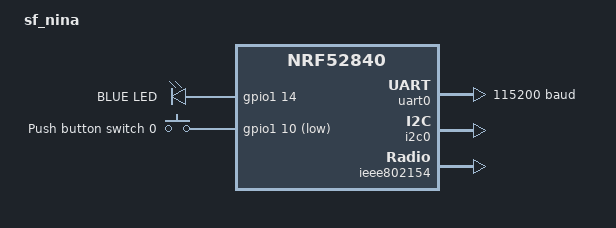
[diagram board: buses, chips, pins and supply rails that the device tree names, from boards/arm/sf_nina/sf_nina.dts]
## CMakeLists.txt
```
# SPDX-License-Identifier: Apache-2.0

cmake_minimum_required(VERSION 3.20.0)

find_package(Zephyr REQUIRED HINTS $ENV{ZEPHYR_BASE})
project(hello_world)

#target_sources(app PRIVATE src/main.c)

FILE(GLOB app_sources src/*.c)
# NORDIC SDK APP START
target_sources(app PRIVATE ${app_sources})
# NORDIC SDK APP END
```

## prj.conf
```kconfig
# nothing here

CONFIG_GPIO=y
CONFIG_I2C=y
CONFIG_CBPRINTF_FP_SUPPORT=y
```

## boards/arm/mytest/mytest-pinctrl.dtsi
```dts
&pinctrl {
	uart0_default: uart0_default {
		group1 {
			psels = <NRF_PSEL(UART_TX, 0, 6)>;				
		};
		group2 {
			psels = <NRF_PSEL(UART_RX, 0, 8)>;				
			bias-pull-up;
		};
	};

	uart0_sleep: uart0_sleep {
		group1 {
			psels = <NRF_PSEL(UART_TX, 0, 6)>,
				<NRF_PSEL(UART_RX, 0, 8)>;				
			low-power-enable;
		};
	};
};
```

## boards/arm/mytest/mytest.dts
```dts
// Copyright (c) 2023 Nordic Semiconductor ASA
// SPDX-License-Identifier: Apache-2.0

/dts-v1/;
#include <nordic/nrf52840_qiaa.dtsi>
#include "mytest-pinctrl.dtsi"

/ {
	model = "mytest";
	compatible = "mytest";

	chosen {
		zephyr,sram = &sram0;
		zephyr,flash = &flash0;
		zephyr,code-partition = &slot0_partition;
		zephyr,console = &uart0;
		zephyr,shell-uart = &uart0;
		zephyr,uart-mcumgr = &uart0;
		zephyr,bt-mon-uart = &uart0;
		zephyr,bt-c2h-uart = &uart0;
	};

	leds {
		compatible = "gpio-leds";
		led0: led_0 {
			gpios = <&gpio0 13 GPIO_ACTIVE_LOW>;
			label = "Green LED 0";
		};
	};
};

&uart0 {
	compatible = "nordic,nrf-uarte";
	status = "okay";
	current-speed = <115200>;
	pinctrl-0 = <&uart0_default>;
	pinctrl-1 = <&uart0_sleep>;
	pinctrl-names = "default", "sleep";
};


&flash0 {
	partitions {
		compatible = "fixed-partitions";
		#address-cells = <1>;
		#size-cells = <1>;

		boot_partition: partition@0 {
			label = "mcuboot";
			reg = <0x0 0xc000>;
		};
		slot0_partition: partition@c000 {
			label = "image-0";
			reg = <0xc000 0x72000>;
		};
		slot1_partition: partition@7e000 {
			label = "image-1";
			reg = <0x7e000 0x72000>;
		};
		scratch_partition: partition@f0000 {
			label = "image-scratch";
			reg = <0xf0000 0xa000>;
		};
		storage_partition: partition@fa000 {
			label = "storage";
			reg = <0xfa000 0x6000>;
		};
	};
};
```

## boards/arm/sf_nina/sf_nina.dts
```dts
// Copyright (c) 2023 Nordic Semiconductor ASA
// SPDX-License-Identifier: Apache-2.0

/dts-v1/;
#include <nordic/nrf52840_qiaa.dtsi>
#include "sf_nina-pinctrl.dtsi"

/ {
	model = "sf_nina";
	compatible = "sf,sf-nina";

	chosen {
		zephyr,sram = &sram0;
		zephyr,flash = &flash0;
		zephyr,code-partition = &slot0_partition;
		zephyr,console = &uart0;
		zephyr,shell-uart = &uart0;
		zephyr,uart-mcumgr = &uart0;
		zephyr,bt-mon-uart = &uart0;
		zephyr,bt-c2h-uart = &uart0;
		zephyr,ieee802154 = &ieee802154;
	};

	leds {
		compatible = "gpio-leds";
		ledblue: led_0 {
			gpios = <&gpio1 14 0>;
			label = "BLUE LED";
		};
	};

	buttons {
		compatible = "gpio-keys";
		button0: button_0 {
			gpios = <&gpio1 10 (GPIO_PULL_UP | GPIO_ACTIVE_LOW)>;
			label = "Push button switch 0";
		};
	};

	aliases {
		ledblue = &ledblue;	
		button0 = &button0;	
	};
};

&gpiote {
	status = "okay";
};

&gpio0 {
	status = "okay";
};

&gpio1 {
	status = "okay";
};

&uart0 {
	compatible = "nordic,nrf-uarte";
	status = "okay";
	current-speed = <115200>;
	pinctrl-0 = <&uart0_default>;
	pinctrl-1 = <&uart0_sleep>;
	pinctrl-names = "default", "sleep";
};

&i2c0 {
	compatible = "nordic,nrf-twi";
	status = "okay";
	pinctrl-0 = <&i2c0_default>;
	pinctrl-1 = <&i2c0_sleep>;
	pinctrl-names = "default", "sleep";
};


&flash0 {
	partitions {
		compatible = "fixed-partitions";
		#address-cells = <1>;
		#size-cells = <1>;

		boot_partition: partition@0 {
			label = "mcuboot";
			reg = <0x0 0xc000>;
		};
		slot0_partition: partition@c000 {
			label = "image-0";
			reg = <0xc000 0x72000>;
		};
		slot1_partition: partition@7e000 {
			label = "image-1";
			reg = <0x7e000 0x72000>;
		};
		scratch_partition: partition@f0000 {
			label = "image-scratch";
			reg = <0xf0000 0xa000>;
		};
		storage_partition: partition@fa000 {
			label = "storage";
			reg = <0xfa000 0x6000>;
		};
	};
};

&ieee802154 {
	status = "okay";
};
```

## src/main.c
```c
/*
 * Copyright (c) 2012-2014 Wind River Systems, Inc.
 *
 * SPDX-License-Identifier: Apache-2.0
 */

#include <zephyr/kernel.h>

#include "pin_manager.h"
#include "ism330.h"

#define SLEEP_MS 200


// Define the callback function
void button_pressed(const struct device *dev, struct gpio_callback *cb, uint32_t pins)
{
	LEDBLUE_Toggle();
}

// Define a variable of type static struct gpio_callback
static struct gpio_callback button_cb_data;

void main(void)
{
	uint8_t val;

	printk("Hello World from my new board! %s\n", CONFIG_BOARD);

	PIN_MANAGER_Initialize();
	ISM_Initialize();


	// Initialize the gpio_callback variable  
	gpio_init_callback(&button_cb_data, button_pressed, BIT(button.pin)); 	
	
	// Add the callback function by calling gpio_add_callback()
 	gpio_add_callback(button.port, &button_cb_data);

	LEDBLUE_SetHigh();
	k_msleep(SLEEP_MS);	
	LEDBLUE_SetLow();


/*
	//Test ledblue
	while(1) {
		LEDBLUE_SetHigh();
		k_msleep(SLEEP_MS);	
		LEDBLUE_SetLow();
		k_msleep(SLEEP_MS);	

	}
*/

/*
	//Test button as dig. input
	while(1) {
		val = gpio_pin_get_dt(&button);
		if (val) {
			LEDBLUE_SetHigh();
		} else {
			LEDBLUE_SetLow();
		}
		k_msleep(SLEEP_MS);

		printRawAccel();
	}
*/

	//Tetst button as interrupt
	while (1) {
		printRawAccel();
		k_msleep(SLEEP_MS);
	}

}
```

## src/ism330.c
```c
#include "ism330.h"
#include <stdlib.h>
//#include "math.h"

int16_t data_raw_acceleration[3];
int16_t data_raw_angular_rate[3];
//static int16_t data_raw_temperature;
float acceleration_mg[3];
float angular_rate_mdps[3];
//static float temperature_degC;
uint8_t whoamI, rst;
//static uint8_t tx_buffer[1000];

gyro_angle ISM_gyro_angle;
accel ISM_accel;

stmdev_ctx_t dev_ctx;

int32_t platform_write(void *handle, uint8_t reg, const uint8_t *bufp,
                              uint16_t len)
{
#if defined(NUCLEO_F411RE)
  HAL_I2C_Mem_Write(handle, ISM330DHCX_I2C_ADD_H, reg,
                    I2C_MEMADD_SIZE_8BIT, (uint8_t*) bufp, len, 1000);
#elif defined(STEVAL_MKI109V3)
  HAL_GPIO_WritePin(CS_up_GPIO_Port, CS_up_Pin, GPIO_PIN_RESET);
  HAL_SPI_Transmit(handle, &reg, 1, 1000);
  HAL_SPI_Transmit(handle, (uint8_t*) bufp, len, 1000);
  HAL_GPIO_WritePin(CS_up_GPIO_Port, CS_up_Pin, GPIO_PIN_SET);
#elif defined(SPC584B_DIS)
  i2c_lld_write(handle,  ISM330DHCX_I2C_ADD_H & 0xFE, reg,
               (uint8_t*) bufp, len);
#endif

	uint8_t buffer[16];
	uint8_t i,aux;
	int32_t ret; 

	buffer[0] = reg;

	aux = 1;
	for (i = 0; i < len; i++) {
		buffer[aux] = bufp[i];
		aux++;
	}
	//SPI_transaction(buffer, aux);

	ret = i2c_write_dt(&dev_i2c, buffer, aux);

	return 0;
}

/*
 * @brief  Read generic device register (platform dependent)
 *
 * @param  handle    customizable argument. In this examples is used in
 *                   order to select the correct sensor bus handler.
 * @param  reg       register to read
 * @param  bufp      pointer to buffer that store the data read
 * @param  len       number of consecutive register to read
 *
 */
int32_t platform_read(void *handle, uint8_t reg, uint8_t *bufp,
                             uint16_t len)
{
#if defined(NUCLEO_F411RE)
  HAL_I2C_Mem_Read(handle, ISM330DHCX_I2C_ADD_H, reg,
                   I2C_MEMADD_SIZE_8BIT, bufp, len, 1000);
#elif defined(STEVAL_MKI109V3)
  reg |= 0x80;
  HAL_GPIO_WritePin(CS_up_GPIO_Port, CS_up_Pin, GPIO_PIN_RESET);
  HAL_SPI_Transmit(handle, &reg, 1, 1000);
  HAL_SPI_Receive(handle, bufp, len, 1000);
  HAL_GPIO_WritePin(CS_up_GPIO_Port, CS_up_Pin, GPIO_PIN_SET);
#elif defined(SPC584B_DIS)
  i2c_lld_read(handle, ISM330DHCX_I2C_ADD_H & 0xFE, reg, bufp, len);
#endif

	uint8_t buffer[16];
	uint8_t i,aux;
	uint32_t ret;

	//uint8_t reading[1]= {0};
    uint8_t sensor_regs[1];
	
	sensor_regs[0] = reg;
	ret = i2c_write_read_dt(&dev_i2c,&sensor_regs[0],1,bufp,len);

	return 0;
}

int ISM_Initialize(void)
{
 	
	//printk("I2C Accel Tests\n");

	if (!device_is_ready(dev_i2c.bus)) {
		printk("I2C bus %s is not ready!\n\r",dev_i2c.bus->name);		
    return 0;
	}


	  /* Initialize mems driver interface */
	dev_ctx.write_reg = platform_write;
	dev_ctx.read_reg = platform_read;

	k_msleep(SLEEP_MS);

	/* Check device ID */
	ism330dhcx_device_id_get(&dev_ctx, &whoamI);
	printk("ISM whoiam %x\n", whoamI);

  /* Restore default configuration */
  ism330dhcx_reset_set(&dev_ctx, PROPERTY_ENABLE);
  do {
    ism330dhcx_reset_get(&dev_ctx, &rst);
    printk("ISM resetting dev %x\n", rst);
  } while (rst);

  /* Start device configuration. */
  ism330dhcx_device_conf_set(&dev_ctx, PROPERTY_ENABLE);
  
  /* Enable Block Data Update */
  ism330dhcx_block_data_update_set(&dev_ctx, PROPERTY_ENABLE);

  /* Set Output Data Rate */
  ism330dhcx_xl_data_rate_set(&dev_ctx, ISM330DHCX_XL_ODR_104Hz);
  ism330dhcx_gy_data_rate_set(&dev_ctx, ISM330DHCX_GY_ODR_104Hz);

  /* Set full scale */
  ism330dhcx_xl_full_scale_set(&dev_ctx, ISM330DHCX_2g);
  ism330dhcx_gy_full_scale_set(&dev_ctx, ISM330DHCX_2000dps);

  /* Configure filtering chain(No aux interface)
  *
  * Accelerometer - LPF1 + LPF2 path
  */
  ism330dhcx_xl_hp_path_on_out_set(&dev_ctx, ISM330DHCX_LP_ODR_DIV_100);
  ism330dhcx_xl_filter_lp2_set(&dev_ctx, PROPERTY_ENABLE);

  //ism330dhcx_g
  ism330dhcx_gy_lp1_bandwidth_set(&dev_ctx, ISM330DHCX_MEDIUM);
  ism330dhcx_gy_filter_lp1_set(&dev_ctx, PROPERTY_ENABLE);

  ISM_gyro_angle.p = 0;
  ISM_gyro_angle.r = 0;
  ISM_gyro_angle.y = 0;

  ISM_accel.last_accel_y = 0;
  ISM_accel.diff_accel_y = 0;

  ISM_accel.mov_av_buf[0] = 0;
  ISM_accel.mov_av_buf[1] = 0;
  ISM_accel.mov_av_buf[2] = 0;
  ISM_accel.mov_av_buf[3] = 0;

}

void printRawAccel(void)
{
  uint8_t reg;

	ism330dhcx_xl_flag_data_ready_get(&dev_ctx, &reg);

	if (reg) {
    // Read acceleration field data
	  memset(data_raw_acceleration, 0x00, 3 * sizeof(int16_t));
	  ism330dhcx_acceleration_raw_get(&dev_ctx, data_raw_acceleration);
	  acceleration_mg[0] = ism330dhcx_from_fs2g_to_mg(data_raw_acceleration[0]);
	  acceleration_mg[1] = ism330dhcx_from_fs2g_to_mg(data_raw_acceleration[1]);
	  acceleration_mg[2] = ism330dhcx_from_fs2g_to_mg(data_raw_acceleration[2]);
	  //sprintf((char *)tx_buffer,"Acceleration [mg]:%4.2f\t%4.2f\t%4.2f\r\n", acceleration_mg[0], acceleration_mg[1], acceleration_mg[2]);
	  printf("Accel [mg]:%4.2f\t%4.2f\t%4.2f\r\n", acceleration_mg[0], acceleration_mg[1], acceleration_mg[2]);
	  //printf("Accel z [mg]:%4.2f\n", (acceleration_mg[2]+119));
  }

}

void printRawAng(void)
{
  uint8_t reg;

  ism330dhcx_gy_flag_data_ready_get(&dev_ctx, &reg);

	if (reg) {
    // Read angular rate field data
		memset(data_raw_angular_rate, 0x00, 3 * sizeof(int16_t));
		ism330dhcx_angular_rate_raw_get(&dev_ctx, data_raw_angular_rate);
		angular_rate_mdps[0] = ism330dhcx_from_fs2000dps_to_mdps(data_raw_angular_rate[0]);
		angular_rate_mdps[1] = ism330dhcx_from_fs2000dps_to_mdps(data_raw_angular_rate[1]);
		angular_rate_mdps[2] = ism330dhcx_from_fs2000dps_to_mdps(data_raw_angular_rate[2]);
		//printf("Angrate [mdps]:%4.2f\t%4.2f\t%4.2f\r\n", angular_rate_mdps[0], angular_rate_mdps[1], angular_rate_mdps[2]);
    //printf("Angrate [mdps]:%6.0f\t%6.0f\t%6.0f\r\n", angular_rate_mdps[0], angular_rate_mdps[1], angular_rate_mdps[2]);
    printf("Angrate [dps]:%3.1f\t%3.1f\t%3.1f\r\n", angular_rate_mdps[0]/1000, angular_rate_mdps[1]/1000, angular_rate_mdps[2]/1000);
  }

}

float_t gyro_fs2000dps_to_dps(int16_t lsb)
{
  //return ((float_t)lsb * 70.0f);
  return ((float_t)lsb * 0.07f);
}

int getRawAngDeg(void)
{
uint8_t reg;
int16_t p,r,y;

  ism330dhcx_gy_flag_data_ready_get(&dev_ctx, &reg);

	if (reg) {
    
		memset(data_raw_angular_rate, 0x00, 3 * sizeof(int16_t));
		ism330dhcx_angular_rate_raw_get(&dev_ctx, data_raw_angular_rate);
		angular_rate_mdps[0] = gyro_fs2000dps_to_dps(data_raw_angular_rate[0]);
		angular_rate_mdps[1] = gyro_fs2000dps_to_dps(data_raw_angular_rate[1]);
		angular_rate_mdps[2] = gyro_fs2000dps_to_dps(data_raw_angular_rate[2]);
		
    
//    printf("Angrate [dps]:%3.1f\t%3.1f\t%3.1f\r\n", angular_rate_mdps[0], angular_rate_mdps[1], angular_rate_mdps[2]);
    
    ISM_gyro_angle.r = angular_rate_mdps[0]; //Y movement mouse
    ISM_gyro_angle.p = angular_rate_mdps[1]; // to scroll wheel
    ISM_gyro_angle.y = angular_rate_mdps[2]; //X movement mouse

    if (abs(ISM_gyro_angle.r) || abs(ISM_gyro_angle.p) || abs(ISM_gyro_angle.y)) {
      //printf("Angrate [d]:%d\t%d\t%d\r\n", ISM_gyro_angle.r, ISM_gyro_angle.p, ISM_gyro_angle.y);
      return 1;
    }     
  }
  return 0;
}

int getRawAccMg(void)
{
    //int16_t noise;
    uint8_t reg;

	  ism330dhcx_xl_flag_data_ready_get(&dev_ctx, &reg);

	  if (reg) {
      // Read acceleration field data
	    memset(data_raw_acceleration, 0x00, 3 * sizeof(int16_t));
	    ism330dhcx_acceleration_raw_get(&dev_ctx, data_raw_acceleration);
	    acceleration_mg[0] = ism330dhcx_from_fs2g_to_mg(data_raw_acceleration[0]);
	    acceleration_mg[1] = ism330dhcx_from_fs2g_to_mg(data_raw_acceleration[1]);
	    acceleration_mg[2] = ism330dhcx_from_fs2g_to_mg(data_raw_acceleration[2]);
	    //sprintf((char *)tx_buffer,"Acceleration [mg]:%4.2f\t%4.2f\t%4.2f\r\n", acceleration_mg[0], acceleration_mg[1], acceleration_mg[2]);
	    //printf("Accel [mg]:%4.2f\t%4.2f\t%4.2f\r\n", acceleration_mg[0], acceleration_mg[1], acceleration_mg[2]);
	    //printf("Accel z [mg]:%4.2f\n", (acceleration_mg[2]+119));
            
      //Derivation of acceletation in order to eliminate gravity
      ISM_accel.diff_accel_y = acceleration_mg[1] - ISM_accel.last_accel_y; 
      ISM_accel.last_accel_y = acceleration_mg[1];

      //printf("Accel y]:%d\n",ISM_accel.diff_accel_y);

    }

    return 1;
}
```

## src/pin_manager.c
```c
#include "pin_manager.h"

//static struct gpio_dt_spec led = GPIO_DT_SPEC_GET(LEDBLUE_NODE, gpios);

void PIN_MANAGER_Initialize (void)
{
    int ret;

    /* Configure LEDBLUE */
	if (!device_is_ready(led.port)) {
		return;
	}

	ret = gpio_pin_configure_dt(&led, GPIO_OUTPUT_ACTIVE);
	if (ret < 0) {
		return;
	}

	/* Configure BUTTON0 */
	
	if (!device_is_ready(button.port)) {
		return;
	}

	ret = gpio_pin_configure_dt(&button, GPIO_INPUT | GPIO_PULL_UP);
	if (ret < 0) {
		return;
	}

	//Configure the interrupt on the button's pin 
	ret = gpio_pin_interrupt_configure_dt(&button, GPIO_INT_EDGE_TO_ACTIVE );
	
}
```

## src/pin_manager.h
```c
#ifndef PIN_MANAGER_H
#define PIN_MANAGER_H

#include <zephyr/kernel.h>
#include <zephyr/drivers/gpio.h>
#include <zephyr/device.h>
#include <zephyr/devicetree.h>


//LEDBLUE 
#define LEDBLUE_NODE DT_NODELABEL(ledblue)
static const struct gpio_dt_spec led = GPIO_DT_SPEC_GET(LEDBLUE_NODE, gpios);

//BUTTON0
#define BUTTON0_NODE DT_NODELABEL(button0)
static const struct gpio_dt_spec button = GPIO_DT_SPEC_GET(BUTTON0_NODE, gpios);

#define LEDBLUE_SetHigh()   gpio_pin_set_dt(&led,1)
#define LEDBLUE_SetLow()    gpio_pin_set_dt(&led,0)
#define LEDBLUE_Toggle()    gpio_pin_toggle_dt(&led);

void PIN_MANAGER_Initialize (void);


#endif
```
